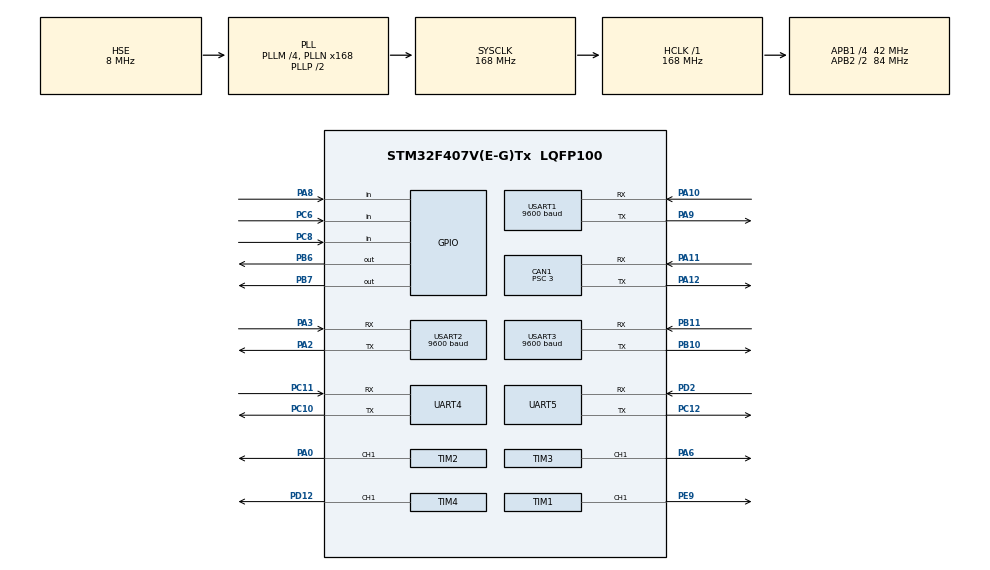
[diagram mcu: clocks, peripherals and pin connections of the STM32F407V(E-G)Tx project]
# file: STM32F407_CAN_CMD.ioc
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CAN1.ABOM=ENABLE
CAN1.BS1=CAN_BS1_9TQ
CAN1.BS2=CAN_BS2_4TQ
CAN1.CalculateBaudRate=1000000
CAN1.CalculateTimeBit=1000
CAN1.CalculateTimeQuantum=71.42857142857143
CAN1.Prescaler=3
Dma.MEMTOMEM.0.Direction=DMA_MEMORY_TO_MEMORY
Dma.MEMTOMEM.0.FIFOMode=DMA_FIFOMODE_ENABLE
Dma.MEMTOMEM.0.FIFOThreshold=DMA_FIFO_THRESHOLD_FULL
Dma.MEMTOMEM.0.Instance=DMA2_Stream1
Dma.MEMTOMEM.0.MemBurst=DMA_MBURST_SINGLE
Dma.MEMTOMEM.0.MemDataAlignment=DMA_MDATAALIGN_BYTE
Dma.MEMTOMEM.0.MemInc=DMA_MINC_ENABLE
Dma.MEMTOMEM.0.Mode=DMA_NORMAL
Dma.MEMTOMEM.0.PeriphBurst=DMA_PBURST_SINGLE
Dma.MEMTOMEM.0.PeriphDataAlignment=DMA_PDATAALIGN_BYTE
Dma.MEMTOMEM.0.PeriphInc=DMA_PINC_ENABLE
Dma.MEMTOMEM.0.Priority=DMA_PRIORITY_LOW
Dma.Request0=MEMTOMEM
Dma.Request1=USART1_RX
Dma.USART1_RX.1.Direction=DMA_PERIPH_TO_MEMORY
Dma.USART1_RX.1.FIFOMode=DMA_FIFOMODE_DISABLE
Dma.USART1_RX.1.Instance=DMA2_Stream2
Dma.USART1_RX.1.MemDataAlignment=DMA_MDATAALIGN_BYTE
Dma.USART1_RX.1.MemInc=DMA_MINC_ENABLE
Dma.USART1_RX.1.Mode=DMA_NORMAL
Dma.USART1_RX.1.PeriphDataAlignment=DMA_PDATAALIGN_BYTE
Dma.USART1_RX.1.PeriphInc=DMA_PINC_DISABLE
Dma.USART1_RX.1.Priority=DMA_PRIORITY_LOW
Mcu.Family=STM32F4
Mcu.Name=STM32F407V(E-G)Tx
Mcu.Package=LQFP100
NVIC.CAN1_RX0_IRQn=true\:0\:0\:false\:false\:true\:true\:true\:true
NVIC.DMA2_Stream2_IRQn=true\:0\:0\:false\:false\:true\:false\:true\:true
NVIC.PriorityGroup=NVIC_PRIORITYGROUP_4
NVIC.TIM7_IRQn=true\:0\:0\:false\:false\:true\:true\:true\:true
NVIC.USART1_IRQn=true\:0\:0\:false\:false\:true\:true\:true\:true
PA0-WKUP.Signal=S_TIM2_CH1_ETR
PA10.Mode=Asynchronous
PA10.Signal=USART1_RX
PA11.Mode=CAN_Activate
PA11.Signal=CAN1_RX
PA12.Mode=CAN_Activate
PA12.Signal=CAN1_TX
PA13.Mode=Serial_Wire
PA13.Signal=SYS_JTMS-SWDIO
PA14.Mode=Serial_Wire
PA14.Signal=SYS_JTCK-SWCLK
PA2.Mode=Asynchronous
PA2.Signal=USART2_TX
PA3.Mode=Asynchronous
PA3.Signal=USART2_RX
PA6.Signal=S_TIM3_CH1
PA8.GPIO_PuPd=GPIO_PULLUP
PA8.Signal=GPIO_Input
PA9.Mode=Asynchronous
PA9.Signal=USART1_TX
PB10.Mode=Asynchronous
PB10.Signal=USART3_TX
PB11.Mode=Asynchronous
PB11.Signal=USART3_RX
PB6.GPIO_ModeDefaultOutputPP=GPIO_MODE_OUTPUT_PP
PB6.GPIO_PuPd=GPIO_NOPULL
PB6.GPIO_Speed=GPIO_SPEED_FREQ_HIGH
PB6.PinState=GPIO_PIN_SET
PB6.Signal=GPIO_Output
PB7.GPIO_ModeDefaultOutputPP=GPIO_MODE_OUTPUT_PP
PB7.GPIO_PuPd=GPIO_NOPULL
PB7.GPIO_Speed=GPIO_SPEED_FREQ_HIGH
PB7.PinState=GPIO_PIN_SET
PB7.Signal=GPIO_Output
PC10.Mode=Asynchronous
PC10.Signal=UART4_TX
PC11.Mode=Asynchronous
PC11.Signal=UART4_RX
PC12.Mode=Asynchronous
PC12.Signal=UART5_TX
PC14-OSC32_IN.Mode=LSE-External-Oscillator
PC14-OSC32_IN.Signal=RCC_OSC32_IN
PC15-OSC32_OUT.Mode=LSE-External-Oscillator
PC15-OSC32_OUT.Signal=RCC_OSC32_OUT
PC6.GPIO_PuPd=GPIO_PULLUP
PC6.Signal=GPIO_Input
PC8.GPIO_PuPd=GPIO_PULLUP
PC8.Signal=GPIO_Input
PD12.Signal=S_TIM4_CH1
PD2.Mode=Asynchronous
PD2.Signal=UART5_RX
PE9.Signal=S_TIM1_CH1
PH0-OSC_IN.Mode=HSE-External-Oscillator
PH0-OSC_IN.Signal=RCC_OSC_IN
PH1-OSC_OUT.Mode=HSE-External-Oscillator
PH1-OSC_OUT.Signal=RCC_OSC_OUT
ProjectManager.HeapSize=0x200
ProjectManager.StackSize=0x400
ProjectManager.TargetToolchain=CMake
RCC.48MHZClocksFreq_Value=84000000
RCC.AHBFreq_Value=168000000
RCC.APB1CLKDivider=RCC_HCLK_DIV4
RCC.APB1Freq_Value=42000000
RCC.APB1TimFreq_Value=84000000
RCC.APB2CLKDivider=RCC_HCLK_DIV2
RCC.APB2Freq_Value=84000000
RCC.APB2TimFreq_Value=168000000
RCC.CortexFreq_Value=168000000
RCC.HCLKFreq_Value=168000000
RCC.HSE_VALUE=8000000
RCC.HSI_VALUE=16000000
RCC.PLLM=4
RCC.PLLN=168
RCC.PLLSourceVirtual=RCC_PLLSOURCE_HSE
RCC.SYSCLKFreq_VALUE=168000000
RCC.SYSCLKSource=RCC_SYSCLKSOURCE_PLLCLK
RCC.VCOOutputFreq_Value=336000000
SH.S_TIM1_CH1.0=TIM1_CH1,PWM Generation1 CH1
SH.S_TIM2_CH1_ETR.0=TIM2_CH1,PWM Generation1 CH1
SH.S_TIM3_CH1.0=TIM3_CH1,PWM Generation1 CH1
SH.S_TIM4_CH1.0=TIM4_CH1,PWM Generation1 CH1
TIM1.Channel-PWM\ Generation1\ CH1=TIM_CHANNEL_1
TIM2.Channel-PWM\ Generation1\ CH1=TIM_CHANNEL_1
TIM3.Channel-PWM\ Generation1\ CH1=TIM_CHANNEL_1
TIM4.Channel-PWM\ Generation1\ CH1=TIM_CHANNEL_1
TIM7.Period=10000-1
TIM7.Prescaler=84-1
UART4.VirtualMode=Asynchronous
UART5.VirtualMode=Asynchronous
USART1.BaudRate=9600
USART1.VirtualMode=VM_ASYNC
USART2.BaudRate=9600
USART2.VirtualMode=VM_ASYNC
USART3.BaudRate=9600
USART3.VirtualMode=VM_ASYNC
VP_TIM7_VS_ClockSourceINT.Mode=Enable_Timer
board=custom

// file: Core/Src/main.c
/* USER CODE BEGIN Header */
/**
  ******************************************************************************
  * @file           : main.c
  * @brief          : Main program body
  ******************************************************************************
  * @attention
  *
  * <h2><center>&copy; Copyright (c) 2024 STMicroelectronics.
  * All rights reserved.</center></h2>
  *
  * This software component is licensed by ST under BSD 3-Clause license,
  * the "License"; You may not use this file except in compliance with the
  * License. You may obtain a copy of the License at:
  *                        opensource.org/licenses/BSD-3-Clause
  *
  ******************************************************************************
  */
/* USER CODE END Header */
#include "main.h"
#include "can.h"
#include "dma.h"
#include "tim.h"
#include "usart.h"
#include "gpio.h"

/* USER CODE BEGIN Includes */
#include "task.h"
#include "test.h"
#include "QRcode.h"
/* USER CODE END Includes */

void SystemClock_Config(void);

int main(void)
{

  /* MCU Configuration--------------------------------------------------------*/

  /* Reset of all peripherals, Initializes the Flash interface and the Systick. */
  HAL_Init();

  /* Configure the system clock */
  SystemClock_Config();

  /* Initialize all configured peripherals */
  MX_GPIO_Init();
  MX_DMA_Init();
  MX_CAN1_Init();
  MX_TIM7_Init();
  MX_UART5_Init();
  MX_USART1_UART_Init();
  MX_USART2_UART_Init();
  MX_TIM1_Init();
  MX_TIM2_Init();
  MX_TIM3_Init();
  MX_TIM4_Init();
  MX_UART4_Init();
  MX_USART3_UART_Init();
  /* USER CODE BEGIN 2 */
  AGV_QRcode_Init();  /* 扫码模块一直开着：开机就开中断收码，
                         免得码在 QRcode_Task() 之前发完被丢掉 */
  Test_Switch();/* 桌面测试：TEST_MODE=0 时立刻返回；!=0 则跑对应测试并停住，
                   程序不会走到下一行的 AGV_Init()（模式表见 test.h） */
  AGV_Init();   /* 末尾阻塞在 menu_Init() 等A8启动，期间C6/C8切换路线 */

  /* USER CODE END 2 */

  /* Infinite loop */
  /* USER CODE BEGIN WHILE */

  while (1)
  {
    TaskProc();/*进行全部任务*/
    /* USER CODE END WHILE */

  }
}

void SystemClock_Config(void)
{
  RCC_OscInitTypeDef RCC_OscInitStruct = {0};
  RCC_ClkInitTypeDef RCC_ClkInitStruct = {0};

  /** Configure the main internal regulator output voltage
  */
  __HAL_RCC_PWR_CLK_ENABLE();
  __HAL_PWR_VOLTAGESCALING_CONFIG(PWR_REGULATOR_VOLTAGE_SCALE1);

  /** Initializes the RCC Oscillators according to the specified parameters
  * in the RCC_OscInitTypeDef structure.
  */
  RCC_OscInitStruct.OscillatorType = RCC_OSCILLATORTYPE_HSE;
  RCC_OscInitStruct.HSEState = RCC_HSE_ON;
  RCC_OscInitStruct.PLL.PLLState = RCC_PLL_ON;
  RCC_OscInitStruct.PLL.PLLSource = RCC_PLLSOURCE_HSE;
  RCC_OscInitStruct.PLL.PLLM = 4;
  RCC_OscInitStruct.PLL.PLLN = 168;
  RCC_OscInitStruct.PLL.PLLP = RCC_PLLP_DIV2;
  RCC_OscInitStruct.PLL.PLLQ = 4;
  if (HAL_RCC_OscConfig(&RCC_OscInitStruct) != HAL_OK)
  {
    Error_Handler();
  }

  /** Initializes the CPU, AHB and APB buses clocks
  */
  RCC_ClkInitStruct.ClockType = RCC_CLOCKTYPE_HCLK|RCC_CLOCKTYPE_SYSCLK
                              |RCC_CLOCKTYPE_PCLK1|RCC_CLOCKTYPE_PCLK2;
  RCC_ClkInitStruct.SYSCLKSource = RCC_SYSCLKSOURCE_PLLCLK;
  RCC_ClkInitStruct.AHBCLKDivider = RCC_SYSCLK_DIV1;
  RCC_ClkInitStruct.APB1CLKDivider = RCC_HCLK_DIV4;
  RCC_ClkInitStruct.APB2CLKDivider = RCC_HCLK_DIV2;

  if (HAL_RCC_ClockConfig(&RCC_ClkInitStruct, FLASH_LATENCY_5) != HAL_OK)
  {
    Error_Handler();
  }
}

void Error_Handler(void)
{
  /* USER CODE BEGIN Error_Handler_Debug */
  /* User can add his own implementation to report the HAL error return state */

	while(1);

  /* USER CODE END Error_Handler_Debug */
}
